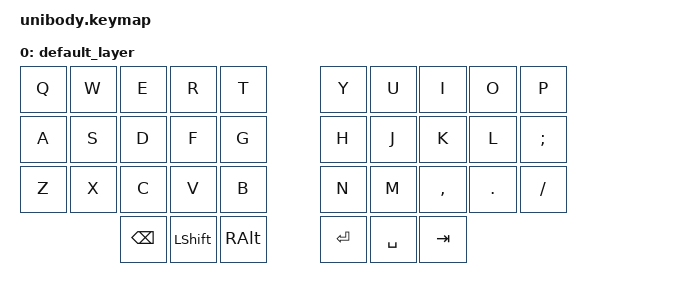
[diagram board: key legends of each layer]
#include <dt-bindings/zmk/keys.h>
#include <behaviors.dtsi>

/ {
    keymap {
        compatible = "zmk,keymap";

        default_layer {
            bindings = <
                &kp Q    &kp W    &kp E    &kp R    &kp T    &kp Y    &kp U    &kp I    &kp O    &kp P
                &kp A    &kp S    &kp D    &kp F    &kp G    &kp H    &kp J    &kp K    &kp L    &kp SEMI
                &kp Z    &kp X    &kp C    &kp V    &kp B    &kp N    &kp M    &kp COMMA&kp DOT  &kp SLASH
                                  &kp BSPC &kp LSHFT&kp RALT &kp ENTER&kp SPACE&kp TAB
            >;
        };
    };
 };
 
